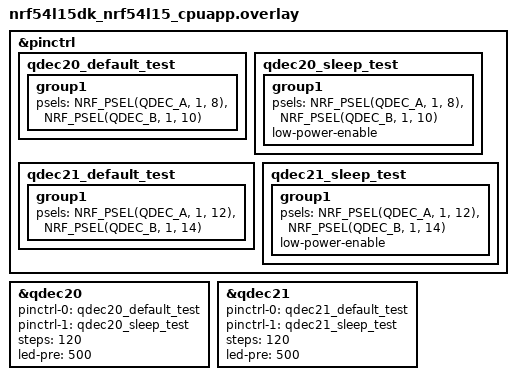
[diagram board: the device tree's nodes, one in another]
/*
 * Copyright (c) 2025 Nordic Semiconductor ASA
 *
 * SPDX-License-Identifier: LicenseRef-Nordic-5-Clause
 */

&pinctrl {
	qdec20_default_test: qdec20_default_test {
		group1 {
			psels = <NRF_PSEL(QDEC_A, 1, 8)>,
				<NRF_PSEL(QDEC_B, 1, 10)>;
		};
	};

	qdec20_sleep_test: qdec20_sleep_test {
		group1 {
			psels = <NRF_PSEL(QDEC_A, 1, 8)>,
				<NRF_PSEL(QDEC_B, 1, 10)>;
			low-power-enable;
		};
	};

	qdec21_default_test: qdec21_default_test {
		group1 {
			psels = <NRF_PSEL(QDEC_A, 1, 12)>,
				<NRF_PSEL(QDEC_B, 1, 14)>;
		};
	};

	qdec21_sleep_test: qdec21_sleep_test {
		group1 {
			psels = <NRF_PSEL(QDEC_A, 1, 12)>,
				<NRF_PSEL(QDEC_B, 1, 14)>;
			low-power-enable;
		};
	};
};

&qdec20 {
	status = "okay";
	pinctrl-0 = <&qdec20_default_test>;
	pinctrl-1 = <&qdec20_sleep_test>;
	pinctrl-names = "default", "sleep";
	steps = <120>;
	led-pre = <500>;
};

&qdec21 {
	status = "okay";
	pinctrl-0 = <&qdec21_default_test>;
	pinctrl-1 = <&qdec21_sleep_test>;
	pinctrl-names = "default", "sleep";
	steps = <120>;
	led-pre = <500>;
};
